# STM32WBA54 register map
File version: 1.0
CPU: CM33 r0p1, little endian, MPU, FPU, 4 interrupt priority bits
Registers are 32-bit, read-write, reset 0x0 unless marked. A register's access mark holds for its fields unless they carry their own. Offsets are from the block's base; [hi:lo] are bit positions.

## USART1 (part 2 of 2) — USART register block
Base 0x40013800
Same registers: USART2 0x40004400, SEC_USART2 0x50004400, SEC_USART1 0x50013800
0x0C BRR — USART baud rate register
  [15:0] BRR — USART baud rate BRR[15:4] BRR[15:4] correspond to USARTDIV[15:4] BRR[3:0] When OVER8 = 0, BRR[3:0] = USARTDIV[3:0]. When OVER8 = 1: BRR[2:0] = USARTDIV[3:0] shifted 1 bit to the right. BRR[3] must be kept cleared.
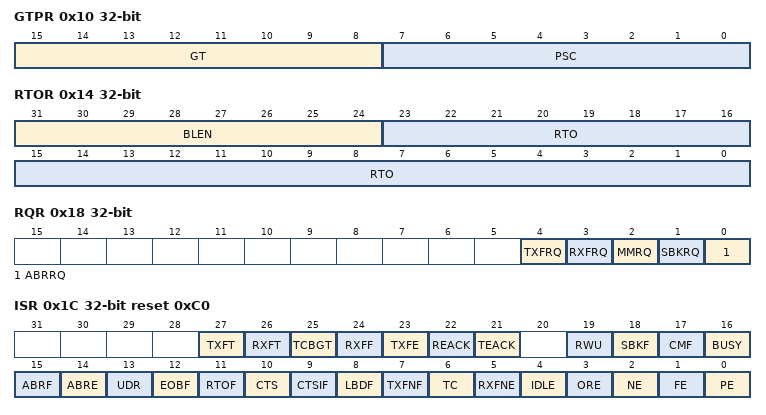
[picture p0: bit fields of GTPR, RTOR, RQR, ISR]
0x10 GTPR — USART guard time and prescaler register
  [15:8] GT — Guard time value This bitfield is used to program the Guard time value in terms of number of baud clock periods. This is used in Smartcard mode. The Transmission Complete flag is set after this guard time value. This bitfield can only be written when the USART is disabled (UE=0). Note: If Smartcard mode is not supported, this bit is reserved and must be kept at reset value. Refer to Section 78.4: USART implementation on page 4565.
  [7:0] PSC — Prescaler value PSC[7:0] = IrDA Normal and Low-power baud rate This bitfield is used for programming the prescaler for dividing the USART source clock to achieve the low-power frequency: The source clock is divided by the value given in the register (8 significant bits): ... PSC[4:0]: Prescaler value This bitfield is used for programming the prescaler for dividing the USART source clock to provide the Smartcard clock. The value given in the register (5 significant bits) is multiplied by 2 to give the division factor of the source clock frequency: ... This bitfield can only be written when the USART is disabled (UE=0). Note: Bits [7:5] must be kept cleared if Smartcard mode is used. Note: This bitfield is reserved and forced by hardware to 0 when the Smartcard and IrDA modes are not supported. Refer to Section 78.4: USART implementation on page 4565.
0x14 RTOR — USART receiver timeout register
  [31:24] BLEN — Block Length This bitfield gives the Block length in Smartcard T=1 Reception. Its value equals the number of information characters + the length of the Epilogue Field (1-LEC/2-CRC) - 1. Examples: BLEN = 0 - 0 information characters + LEC BLEN = 1 - 0 information characters + CRC BLEN = 255 - 254 information characters + CRC (total 256 characters)) In Smartcard mode, the Block length counter is reset when TXE=0 (TXFE = 0 in case FIFO mode is enabled). This bitfield can be used also in other modes. In this case, the Block length counter is reset when RE=0 (receiver disabled) and/or when the EOBCF bit is written to 1. Note: This value can be programmed after the start of the block reception (using the data from the LEN character in the Prologue Field). It must be programmed only once per received block.
  [23:0] RTO — Receiver timeout value This bitfield gives the Receiver timeout value in terms of number of bit duration. In Standard mode, the RTOF flag is set if, after the last received character, no new start bit is detected for more than the RTO value. In Smartcard mode, this value is used to implement the CWT and BWT. See Smartcard chapter for more details. In the standard, the CWT/BWT measurement is done starting from the start bit of the last received character. Note: This value must only be programmed once per received character.
0x18 RQR wo — USART request register
  [4] TXFRQ — Transmit data flush request When FIFO mode is disabled, writing 1 to this bit sets the TXE flag. This enables to discard the transmit data. This bit must be used only in Smartcard mode, when data have not been sent due to errors (NACK) and the FE flag is active in the USART_ISR register. If the USART does not support Smartcard mode, this bit is reserved and must be kept at reset value. When FIFO is enabled, TXFRQ bit is set to flush the whole FIFO. This sets the TXFE flag (Transmit FIFO empty, bit 23 in the USART_ISR register). Flushing the Transmit FIFO is supported in both UART and Smartcard modes. Note: In FIFO mode, the TXFNF flag is reset during the flush request until TxFIFO is empty in order to ensure that no data are written in the data register.
    1=Discard (Set the TXE flags. This allows to discard the transmit data)
  [3] RXFRQ — Receive data flush request Writing 1 to this bit empties the entire receive FIFO i.e. clears the bit RXFNE. This enables to discard the received data without reading them, and avoid an overrun condition.
    1=Discard (clears the RXNE flag. This allows to discard the received data without reading it, and avoid an overrun condition)
  [2] MMRQ — Mute mode request Writing 1 to this bit puts the USART in Mute mode and resets the RWU flag.
    1=Mute (Puts the USART in mute mode and sets the RWU flag)
  [1] SBKRQ — Send break request Writing 1 to this bit sets the SBKF flag and request to send a BREAK on the line, as soon as the transmit machine is available. Note: When the application needs to send the break character following all previously inserted data, including the ones not yet transmitted, the software should wait for the TXE flag assertion before setting the SBKRQ bit.
    1=Break (sets the SBKF flag and request to send a BREAK on the line, as soon as the transmit machine is available)
  [0] ABRRQ — Auto baud rate request Writing 1 to this bit resets the ABRF and ABRE flags in the USART_ISR and requests an automatic baud rate measurement on the next received data frame. Note: If the USART does not support the auto baud rate feature, this bit is reserved and must be kept at reset value. Refer to Section 78.4: USART implementation on page 4565.
    1=Request (resets the ABRF flag in the USART_ISR and request an automatic baud rate measurement on the next received data frame)
0x1C ISR ro reset 0xC0 (reset mask 0xF00FFFFF) — USART interrupt and status register [alternate]
  [27] TXFT — TXFIFO threshold flag This bit is set by hardware when the TXFIFO reaches the threshold programmed in TXFTCFG of USART_CR3 register i.e. the TXFIFO contains TXFTCFG empty locations. An interrupt is generated if the TXFTIE bit =1 (bit 31) in the USART_CR3 register.
    0=NotReached (TXFIFO does not reach the programmed threshold.); 1=Reached (TXFIFO reached the programmed threshold.)
  [26] RXFT — RXFIFO threshold flag This bit is set by hardware when the threshold programmed in RXFTCFG in USART_CR3 register is reached. This means that there are (RXFTCFG - 1) data in the Receive FIFO and one data in the USART_RDR register. An interrupt is generated if the RXFTIE bit =1 (bit 27) in the USART_CR3 register. Note: When the RXFTCFG threshold is configured to 101, RXFT flag is set if 16 data are available i.e. 15 data in the RXFIFO and 1 data in the USART_RDR. Consequently, the 17th received data does not cause an overrun error. The overrun error occurs after receiving the 18th data.
    0=NotReached (Receive FIFO does not reach the programmed threshold.); 1=Reached (Receive FIFO reached the programmed threshold.)
  [25] TCBGT — Transmission complete before guard time flag This bit is set when the last data written in the USART_TDR has been transmitted correctly out of the shift register. It is set by hardware in Smartcard mode, if the transmission of a frame containing data is complete and if the smartcard did not send back any NACK. An interrupt is generated if TCBGTIE=1 in the USART_CR3 register. This bit is cleared by software, by writing 1 to the TCBGTCF in the USART_ICR register or by a write to the USART_TDR register. Note: If the USART does not support the Smartcard mode, this bit is reserved and kept at reset value. If the USART supports the Smartcard mode and the Smartcard mode is enabled, the TCBGT reset value is 1. Refer to Section 78.4: USART implementation on page 4565.
    0=NotCompleted (Transmission is not complete or transmission is complete unsuccessfully (i.e. a NACK is received from the card)); 1=Completed (Transmission is complete successfully (before Guard time completion and there is no NACK from the smart card))
  [24] RXFF — RXFIFO Full This bit is set by hardware when the number of received data corresponds to RXFIFO size + 1 (RXFIFO full + 1 data in the USART_RDR register. An interrupt is generated if the RXFFIE bit =1 in the USART_CR1 register.
    0=NotFull (RXFIFO not full.); 1=Full (RXFIFO Full.)
  [23] TXFE — TXFIFO Empty This bit is set by hardware when TXFIFO is Empty. When the TXFIFO contains at least one data, this flag is cleared. The TXFE flag can also be set by writing 1 to the bit TXFRQ (bit 4) in the USART_RQR register. An interrupt is generated if the TXFEIE bit =1 (bit 30) in the USART_CR1 register.
    0=NotEmpty (TXFIFO not empty.); 1=Empty (TXFIFO empty.)
  [22] REACK — Receive enable acknowledge flag This bit is set/reset by hardware, when the Receive Enable value is taken into account by the USART. It can be used to verify that the USART is ready for reception before entering low-power mode. Note: If the USART does not support the wakeup from Stop feature, this bit is reserved and kept at reset value. Refer to Section 78.4: USART implementation on page 4565.
  [21] TEACK — Transmit enable acknowledge flag This bit is set/reset by hardware, when the Transmit Enable value is taken into account by the USART. It can be used when an idle frame request is generated by writing TE=0, followed by TE=1 in the USART_CR1 register, in order to respect the TE=0 minimum period.
  [19] RWU — Receiver wakeup from Mute mode This bit indicates if the USART is in Mute mode. It is cleared/set by hardware when a wakeup/mute sequence is recognized. The Mute mode control sequence (address or IDLE) is selected by the WAKE bit in the USART_CR1 register. When wakeup on IDLE mode is selected, this bit can only be set by software, writing 1 to the MMRQ bit in the USART_RQR register. Note: If the USART does not support the wakeup from Stop feature, this bit is reserved and kept at reset value. Refer to Section 78.4: USART implementation on page 4565.
  [18] SBKF — Send break flag This bit indicates that a send break character was requested. It is set by software, by writing 1 to the SBKRQ bit in the USART_CR3 register. It is automatically reset by hardware during the stop bit of break transmission.
    0=No break character transmitted; 1=Break character transmitted
  [17] CMF — Character match flag This bit is set by hardware, when a the character defined by ADD[7:0] is received. It is cleared by software, writing 1 to the CMCF in the USART_ICR register. An interrupt is generated if CMIE=1in the USART_CR1 register.
    0=NoMatch (No Character match detected); 1=Match (Character match detected)
  [16] BUSY — Busy flag This bit is set and reset by hardware. It is active when a communication is ongoing on the RX line (successful start bit detected). It is reset at the end of the reception (successful or not).
    0=Idle (USART is idle (no reception)); 1=Busy (Reception on going)
  [15] ABRF — Auto baud rate flag This bit is set by hardware when the automatic baud rate has been set (RXFNE is also set, generating an interrupt if RXFNEIE = 1) or when the auto baud rate operation was completed without success (ABRE=1) (ABRE, RXFNE and FE are also set in this case) It is cleared by software, in order to request a new auto baud rate detection, by writing 1 to the ABRRQ in the USART_RQR register. Note: If the USART does not support the auto baud rate feature, this bit is reserved and kept at reset value.
  [14] ABRE — Auto baud rate error This bit is set by hardware if the baud rate measurement failed (baud rate out of range or character comparison failed) It is cleared by software, by writing 1 to the ABRRQ bit in the USART_RQR register. Note: If the USART does not support the auto baud rate feature, this bit is reserved and kept at reset value.
  [13] UDR — SPI slave underrun error flag In Slave transmission mode, this flag is set when the first clock pulse for data transmission appears while the software has not yet loaded any value into USART_TDR. This flag is reset by setting UDRCF bit in the USART_ICR register. Note: If the USART does not support the SPI slave mode, this bit is reserved and kept at reset value. Refer to Section 78.4: USART implementation on page 4565.
    0=No underrun error; 1=underrun error
  [12] EOBF — End of block flag This bit is set by hardware when a complete block has been received (for example T=1 Smartcard mode). The detection is done when the number of received bytes (from the start of the block, including the prologue) is equal or greater than BLEN + 4. An interrupt is generated if EOBIE = 1 in the USART_CR1 register. It is cleared by software, writing 1 to EOBCF in the USART_ICR register. Note: If Smartcard mode is not supported, this bit is reserved and kept at reset value. Refer to Section 78.4: USART implementation on page 4565.
    0=NotReached (End of Block not reached); 1=Reached (End of Block (number of characters) reached)
  [11] RTOF — Receiver timeout This bit is set by hardware when the timeout value, programmed in the RTOR register has lapsed, without any communication. It is cleared by software, writing 1 to the RTOCF bit in the USART_ICR register. An interrupt is generated if RTOIE=1 in the USART_CR2 register. In Smartcard mode, the timeout corresponds to the CWT or BWT timings. Note: If a time equal to the value programmed in RTOR register separates 2 characters, RTOF is not set. If this time exceeds this value + 2 sample times (2/16 or 2/8, depending on the oversampling method), RTOF flag is set. Note: The counter counts even if RE = 0 but RTOF is set only when RE = 1. If the timeout has already elapsed when RE is set, then RTOF is set. Note: If the USART does not support the Receiver timeout feature, this bit is reserved and kept at reset value.
    0=NotReached (Timeout value not reached); 1=Reached (Timeout value reached without any data reception)
  [10] CTS — CTS flag This bit is set/reset by hardware. It is an inverted copy of the status of the CTS input pin. Note: If the hardware flow control feature is not supported, this bit is reserved and kept at reset value.
    0=Set (CTS line set); 1=Reset (CTS line reset)
  [9] CTSIF — CTS interrupt flag This bit is set by hardware when the CTS input toggles, if the CTSE bit is set. It is cleared by software, by writing 1 to the CTSCF bit in the USART_ICR register. An interrupt is generated if CTSIE=1 in the USART_CR3 register. Note: If the hardware flow control feature is not supported, this bit is reserved and kept at reset value.
    0=NotChanged (No change occurred on the CTS status line); 1=Changed (A change occurred on the CTS status line)
  [8] LBDF — LIN break detection flag This bit is set by hardware when the LIN break is detected. It is cleared by software, by writing 1 to the LBDCF in the USART_ICR. An interrupt is generated if LBDIE = 1 in the USART_CR2 register. Note: If the USART does not support LIN mode, this bit is reserved and kept at reset value. Refer to Section 78.4: USART implementation on page 4565.
    0=NotDetected (LIN break not detected); 1=Detected (LIN break detected)
  [7] TXFNF — TXFIFO not full TXFNF is set by hardware when TXFIFO is not full meaning that data can be written in the USART_TDR. Every write operation to the USART_TDR places the data in the TXFIFO. This flag remains set until the TXFIFO is full. When the TXFIFO is full, this flag is cleared indicating that data can not be written into the USART_TDR. An interrupt is generated if the TXFNFIE bit =1 in the USART_CR1 register. Note: The TXFNF is kept reset during the flush request until TXFIFO is empty. After sending the flush request (by setting TXFRQ bit), the flag TXFNF should be checked prior to writing in TXFIFO (TXFNF and TXFE is set at the same time). Note: This bit is used during single buffer transmission.
    0=Full (Transmit FIFO is full); 1=NotFull (Transmit FIFO is not full)
  [6] TC — Transmission complete This bit indicates that the last data written in the USART_TDR has been transmitted out of the shift register. The TC flag behaves as follows: When TDN = 0, the TC flag is set when the transmission of a frame containing data is complete and when TXE/TXFE is set. When TDN is equal to the number of data in the TXFIFO, the TC flag is set when TXFIFO is empty and TDN is reached. When TDN is greater than the number of data in the TXFIFO, TC remains cleared until the TXFIFO is filled again to reach the programmed number of data to be transferred. When TDN is less than the number of data in the TXFIFO, TC is set when TDN is reached even if the TXFIFO is not empty. An interrupt is generated if TCIE=1 in the USART_CR1 register. TC bit is cleared by software by writing 1 to the TCCF in the USART_ICR register or by writing to the USART_TDR register.
    0=TxNotComplete (Transmission is not complete); 1=TxComplete (Transmission is complete)
  [5] RXFNE — RXFIFO not empty RXFNE bit is set by hardware when the RXFIFO is not empty, meaning that data can be read from the USART_RDR register. Every read operation from the USART_RDR frees a location in the RXFIFO. RXFNE is cleared when the RXFIFO is empty. The RXFNE flag can also be cleared by writing 1 to the RXFRQ in the USART_RQR register. An interrupt is generated if RXFNEIE=1 in the USART_CR1 register.
    0=NoData (Data is not received); 1=DataReady (Received data is ready to be read)
  [4] IDLE — Idle line detected This bit is set by hardware when an Idle Line is detected. An interrupt is generated if IDLEIE=1 in the USART_CR1 register. It is cleared by software, writing 1 to the IDLECF in the USART_ICR register. Note: The IDLE bit is not set again until the RXFNE bit has been set (i.e. a new idle line occurs). Note: If Mute mode is enabled (MME=1), IDLE is set if the USART is not mute (RWU=0), whatever the Mute mode selected by the WAKE bit. If RWU=1, IDLE is not set.
    0=No Idle Line is detected; 1=Idle Line is detected
  [3] ORE — Overrun error This bit is set by hardware when the data currently being received in the shift register is ready to be transferred into the USART_RDR register while RXFF = 1. It is cleared by a software, writing 1 to the ORECF, in the USART_ICR register. An interrupt is generated if RXFNEIE=1 or EIE = 1 in the USART_CR1 register. Note: When this bit is set, the USART_RDR register content is not lost but the shift register is overwritten. An interrupt is generated if the ORE flag is set during multi buffer communication if the EIE bit is set. Note: This bit is permanently forced to 0 (no overrun detection) when the bit OVRDIS is set in the USART_CR3 register.
    0=No Overrun error; 1=Overrun error is detected
  [2] NE — Noise detection flag This bit is set by hardware when noise is detected on a received frame. It is cleared by software, writing 1 to the NFCF bit in the USART_ICR register. Note: This bit does not generate an interrupt as it appears at the same time as the RXFNE bit which itself generates an interrupt. An interrupt is generated when the NE flag is set during multi buffer communication if the EIE bit is set. Note: When the line is noise-free, the NE flag can be disabled by programming the ONEBIT bit to 1 to increase the USART tolerance to deviations (Refer to Section 78.5.9: Tolerance of the USART receiver to clock deviation on page 4584). Note: This error is associated with the character in the USART_RDR.
    0=No noise is detected; 1=Noise is detected
  [1] FE — Framing error This bit is set by hardware when a de-synchronization, excessive noise or a break character is detected. It is cleared by software, writing 1 to the FECF bit in the USART_ICR register. When transmitting data in Smartcard mode, this bit is set when the maximum number of transmit attempts is reached without success (the card NACKs the data frame). An interrupt is generated if EIE = 1 in the USART_CR1 register. Note: This error is associated with the character in the USART_RDR.
    0=NoError (No Framing error is detected); 1=Error (Framing error or break character is detected)
  [0] PE — Parity error This bit is set by hardware when a parity error occurs in Reception mode. It is cleared by software, writing 1 to the PECF in the USART_ICR register. An interrupt is generated if PEIE = 1 in the USART_CR1 register. Note: This error is associated with the character in the USART_RDR.
    0=NoError (No parity error); 1=Error (Parity error)
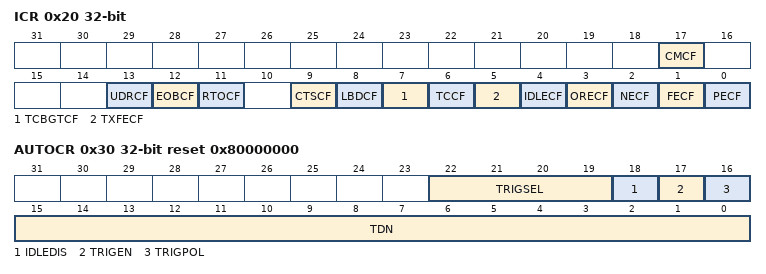
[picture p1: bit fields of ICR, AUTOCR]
0x20 ICR wo — USART interrupt flag clear register
  [17] CMCF write-1-clears — Character match clear flag Writing 1 to this bit clears the CMF flag in the USART_ISR register.
    1=Clears the CMF flag in the ISR register
  [13] UDRCF write-1-clears — SPI slave underrun clear flag Writing 1 to this bit clears the UDRF flag in the USART_ISR register. Note: If the USART does not support SPI slave mode, this bit is reserved and must be kept at reset value. Refer to Section 78.4: USART implementation on page 4565
    1=Clear the UDR flag in the ISR register
  [12] EOBCF write-1-clears — End of block clear flag Writing 1 to this bit clears the EOBF flag in the USART_ISR register. Note: If the USART does not support Smartcard mode, this bit is reserved and must be kept at reset value. Refer to Section 78.4: USART implementation on page 4565.
    1=Clears the EOBF flag in the ISR register
  [11] RTOCF write-1-clears — Receiver timeout clear flag Writing 1 to this bit clears the RTOF flag in the USART_ISR register. Note: If the USART does not support the Receiver timeout feature, this bit is reserved and must be kept at reset value. Refer to Section 78.4: USART implementation on page 4565.
    1=Clears the RTOF flag in the ISR register
  [9] CTSCF write-1-clears — CTS clear flag Writing 1 to this bit clears the CTSIF flag in the USART_ISR register. Note: If the hardware flow control feature is not supported, this bit is reserved and must be kept at reset value. Refer to Section 78.4: USART implementation on page 4565.
    1=Clears the CTSIF flag in the ISR register
  [8] LBDCF write-1-clears — LIN break detection clear flag Writing 1 to this bit clears the LBDF flag in the USART_ISR register. Note: If LIN mode is not supported, this bit is reserved and must be kept at reset value. Refer to Section 78.4: USART implementation on page 4565.
    1=Clears the LBDF flag in the ISR register
  [7] TCBGTCF write-1-clears — Transmission complete before Guard time clear flag Writing 1 to this bit clears the TCBGT flag in the USART_ISR register.
    1=Clear the TCBGT flag in the ISR register
  [6] TCCF write-1-clears — Transmission complete clear flag Writing 1 to this bit clears the TC flag in the USART_ISR register.
    1=Clears the TC flag in the ISR register
  [5] TXFECF write-1-clears — TXFIFO empty clear flag Writing 1 to this bit clears the TXFE flag in the USART_ISR register.
    1=Clear the TXFE flag in the ISR register
  [4] IDLECF write-1-clears — Idle line detected clear flag Writing 1 to this bit clears the IDLE flag in the USART_ISR register.
    1=Clears the IDLE flag in the ISR register
  [3] ORECF write-1-clears — Overrun error clear flag Writing 1 to this bit clears the ORE flag in the USART_ISR register.
    1=Clears the ORE flag in the ISR register
  [2] NECF write-1-clears — Noise detected clear flag Writing 1 to this bit clears the NE flag in the USART_ISR register.
    1=Clears the NF flag in the ISR register
  [1] FECF write-1-clears — Framing error clear flag Writing 1 to this bit clears the FE flag in the USART_ISR register.
    1=Clears the FE flag in the ISR register
  [0] PECF write-1-clears — Parity error clear flag Writing 1 to this bit clears the PE flag in the USART_ISR register.
    1=Clears the PE flag in the ISR register
0x24 RDR ro — USART receive data register
  [8:0] RDR — Receive data value Contains the received data character. The RDR register provides the parallel interface between the input shift register and the internal bus (see Figure 927). When receiving with the parity enabled, the value read in the MSB bit is the received parity bit.
0x28 TDR — USART transmit data register
  [8:0] TDR — Transmit data value Contains the data character to be transmitted. The USART_TDR register provides the parallel interface between the internal bus and the output shift register (see Figure 927). When transmitting with the parity enabled (PCE bit set to 1 in the USART_CR1 register), the value written in the MSB (bit 7 or bit 8 depending on the data length) has no effect because it is replaced by the parity. Note: This register must be written only when TXE/TXFNF=1.
0x2C PRESC — USART prescaler register
  [3:0] PRESCALER — Clock prescaler The USART input clock can be divided by a prescaler factor: Remaining combinations: Reserved Note: When PRESCALER is programmed with a value different of the allowed ones, programmed prescaler value is equal to 1011 i.e. input clock divided by 256.
    0=Div1 (Input clock divided by 1); 1=Div2 (Input clock divided by 2); 2=Div4 (Input clock divided by 4); 3=Div6 (Input clock divided by 6); 4=Div8 (Input clock divided by 8); 5=Div10 (Input clock divided by 10); 6=Div12 (Input clock divided by 12); 7=Div16 (Input clock divided by 16); 8=Div32 (Input clock divided by 32); 9=Div64 (Input clock divided by 64); 10=Div128 (Input clock divided by 128); 11=Div256 (Input clock divided by 256)
0x30 AUTOCR reset 0x80000000 — USART Autonomous mode control register
  [22:19] TRIGSEL — Trigger selection bits Refer to Description of USART interconnections. This bitfield can be written only when the UE bit is cleared in USART_CR1 register. ... Note: This bitfield can be written only when the UE bit of USART_CR1 register is cleared.
  [18] IDLEDIS — Idle frame transmission disable bit after enabling the transmitter Note: This bitfield can be written only when the UE bit of USART_CR1 register is cleared.
  [17] TRIGEN — Trigger enable bit Note: This bitfield can be written only when the UE bit of USART_CR1 register is cleared. Note: When a trigger is detected, TE is set to 1 in USART_CR1 and the data transfer is launched.
  [16] TRIGPOL — Trigger polarity bit This bitfield can be written only when the UE bit is cleared in USART_CR1 register.
  [15:0] TDN — TDN transmission data number This bitfield enables the programming of the number of data to be transmitted. It can be written only when UE is cleared in USART_CR1.
